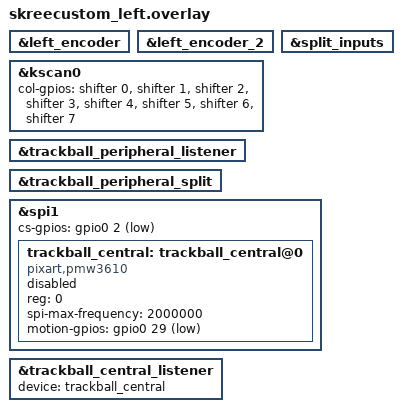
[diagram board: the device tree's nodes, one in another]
/*
 * Skreecustom Left Side - Central Half
 */
#include "skreecustom.dtsi"

&left_encoder {
	status = "okay";
};

&left_encoder_2 {
	status = "okay";
};

&kscan0 {
    col-gpios
        = <&shifter 0 GPIO_ACTIVE_HIGH>
        , <&shifter 1 GPIO_ACTIVE_HIGH>
        , <&shifter 2 GPIO_ACTIVE_HIGH>
        , <&shifter 3 GPIO_ACTIVE_HIGH>
        , <&shifter 4 GPIO_ACTIVE_HIGH>
        , <&shifter 5 GPIO_ACTIVE_HIGH>
        , <&shifter 6 GPIO_ACTIVE_HIGH>
        , <&shifter 7 GPIO_ACTIVE_HIGH>
        ;
};

&split_inputs {
    status = "okay";
};

&trackball_peripheral_listener {
    status = "okay";
};
/* Enable input-split on central to receive trackball data from peripheral */
&trackball_peripheral_split {
    status = "okay";
};

&trackball_peripheral_listener {
    status = "okay";
};

#include <zephyr/dt-bindings/input/input-event-codes.h>
&spi1 {
    cs-gpios = <&gpio0 2 GPIO_ACTIVE_LOW>;

    trackball_central: trackball_central@0 {
        status = "disabled";
        compatible = "pixart,pmw3610";
        reg = <0>;
        spi-max-frequency = <2000000>;
        motion-gpios = <&gpio0 29 (GPIO_ACTIVE_LOW | GPIO_PULL_UP)>;
    };
};

// Overrides for the input listener node
&trackball_central_listener {
    status = "okay";
    device = <&trackball_central>;
};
